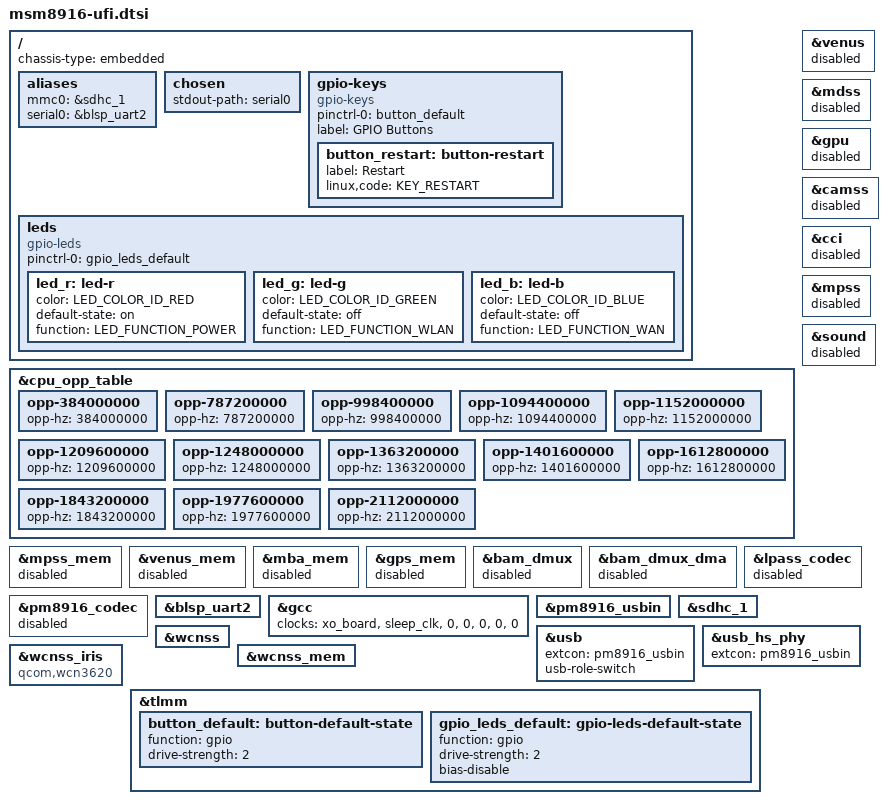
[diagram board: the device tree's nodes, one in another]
// SPDX-License-Identifier: GPL-2.0-only

#include "msm8916-pm8916.dtsi"

#include <dt-bindings/gpio/gpio.h>
#include <dt-bindings/leds/common.h>

/ {
	chassis-type = "embedded";

	aliases {
		mmc0 = &sdhc_1; /* eMMC */
		serial0 = &blsp_uart2;
	};

	chosen {
		stdout-path = "serial0";
	};

	gpio-keys {
		compatible = "gpio-keys";

		pinctrl-0 = <&button_default>;
		pinctrl-names = "default";

		label = "GPIO Buttons";

		/* GPIO is board-specific */
		button_restart: button-restart {
			label = "Restart";
			linux,code = <KEY_RESTART>;
		};
	};

	leds {
		compatible = "gpio-leds";

		pinctrl-0 = <&gpio_leds_default>;
		pinctrl-names = "default";

		/*
		 * GPIOs are board-specific.
		 * Functions and default-states defined here are fallbacks.
		 * Feel free to override them if your board is different.
		 */
		led_r: led-r {
			color = <LED_COLOR_ID_RED>;
			default-state = "on";
			function = LED_FUNCTION_POWER;
		};

		led_g: led-g {
			color = <LED_COLOR_ID_GREEN>;
			default-state = "off";
			function = LED_FUNCTION_WLAN;
		};

		led_b: led-b {
			color = <LED_COLOR_ID_BLUE>;
			default-state = "off";
			function = LED_FUNCTION_WAN;
		};
	};
};

/* --- Overwrite the original CPU OPP table directly --- */
&cpu_opp_table {
	/* Delete original operating points */
	/delete-node/ opp-200000000;
	/delete-node/ opp-400000000;
	/delete-node/ opp-800000000;
	/delete-node/ opp-998400000;

	/* Add new operating points */
	opp-384000000 { opp-hz = /bits/ 64 <384000000>; };
	opp-787200000 { opp-hz = /bits/ 64 <787200000>; };
	opp-998400000 { opp-hz = /bits/ 64 <998400000>; };
	opp-1094400000 { opp-hz = /bits/ 64 <1094400000>; };
	opp-1152000000 { opp-hz = /bits/ 64 <1152000000>; };
	opp-1209600000 { opp-hz = /bits/ 64 <1209600000>; };
	opp-1248000000 { opp-hz = /bits/ 64 <1248000000>; };
	opp-1363200000 { opp-hz = /bits/ 64 <1363200000>; };
	opp-1401600000 { opp-hz = /bits/ 64 <1401600000>; };
	opp-1612800000 { opp-hz = /bits/ 64 <1612800000>; };
	opp-1843200000 { opp-hz = /bits/ 64 <1843200000>; };
	opp-1977600000 { opp-hz = /bits/ 64 <1977600000>; };
	opp-2112000000 { opp-hz = /bits/ 64 <2112000000>; };
};

/* --- Hardware Disable Overrides --- */
/*
 * Disable reserved memory regions instead of deleting them.
 * This keeps their labels valid for references elsewhere in the dtsi files,
 * but tells the kernel not to reserve the actual memory.
 */
&mpss_mem { status = "disabled"; };
&venus_mem { status = "disabled"; };
&mba_mem { status = "disabled"; };
&gps_mem { status = "disabled"; };

/* 1. Disable Video and Display Subsystems */
&venus { status = "disabled"; };
&mdss { status = "disabled"; };
&gpu { status = "disabled"; };

/* 2. Disable Camera Subsystems */
&camss { status = "disabled"; };
&cci { status = "disabled"; };

/* 3. Disable Modem (Cellular) and GPS */
&mpss { status = "disabled"; };
&bam_dmux { status = "disabled"; };
&bam_dmux_dma { status = "disabled"; };

/* 4. Disable Audio Subsystems */
&sound { status = "disabled"; };
&lpass_codec { status = "disabled"; };
&pm8916_codec { status = "disabled"; };

/* 5. Disable Touchscreen (Generic - UFI devices typically lack this) */
/*
 * Note: Touchscreen nodes are board-specific. If one were defined
 * for a UFI device, it would be disabled here. Since none is defined,
 * no action is needed.
 */

/* --- Hardware Enable Section --- */

&blsp_uart2 {
	status = "okay";
};

/* Remove &mdss_dsi0_phy from clocks to make sure that gcc probes with display disabled */
&gcc {
	clocks = <&xo_board>, <&sleep_clk>, <0>, <0>, <0>, <0>, <0>;
};

&pm8916_usbin {
	status = "okay";
};

&sdhc_1 {
	status = "okay";
};

&usb {
	extcon = <&pm8916_usbin>;
	usb-role-switch;

	status = "okay";
};

&usb_hs_phy {
	extcon = <&pm8916_usbin>;
};

/* Wi-Fi related nodes are left enabled as requested */
&wcnss {
	status = "okay";
};

&wcnss_iris {
	compatible = "qcom,wcn3620";
};

&wcnss_mem {
	status = "okay";
};

&tlmm {
	/* pins are board-specific */
	button_default: button-default-state {
		function = "gpio";
		drive-strength = <2>;
	};

	gpio_leds_default: gpio-leds-default-state {
		function = "gpio";
		drive-strength = <2>;
		bias-disable;
	};
};

